# DDR16SS_DDR16SS_CTLPHY_WRAP_CTL_CFG_CTLCFG_0F308000h register map
Vendor: Texas Instruments
Registers are 32-bit, read-write, reset 0x0 unless marked. A register's access mark holds for its fields unless they carry their own. Offsets are as the file gives them; [hi:lo] are bit positions; {n}, {i} and the like mark numbered series.

## DDR16SS_CTLPHY_WRAP_CTL_CFG_CTLCFG (part 5 of 11)
0x5A0 DDR16SS_CTLPHY_WRAP_CTL_CFG_CTLCFG_DENALI_CTL_360 ro
  [31:0] OUT_OF_RANGE_ADDR_0 — Address of command that caused an out-of-range interrupt. READ-ONLY Reset Source: ctl_amod_g_rst_n
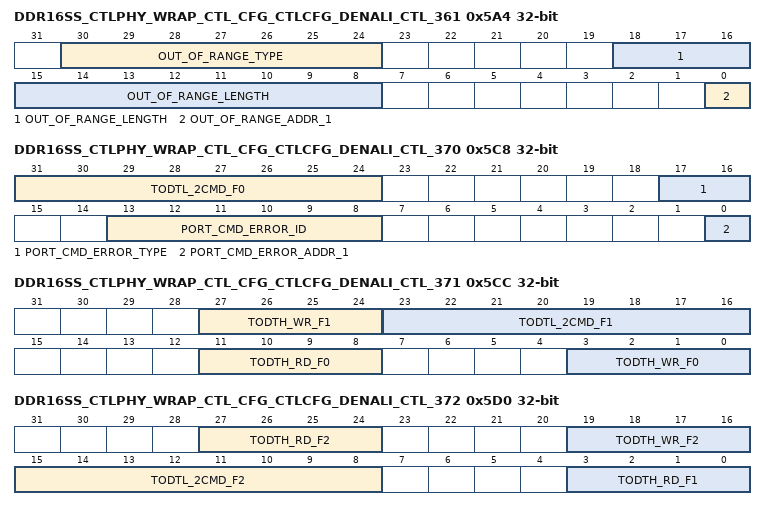
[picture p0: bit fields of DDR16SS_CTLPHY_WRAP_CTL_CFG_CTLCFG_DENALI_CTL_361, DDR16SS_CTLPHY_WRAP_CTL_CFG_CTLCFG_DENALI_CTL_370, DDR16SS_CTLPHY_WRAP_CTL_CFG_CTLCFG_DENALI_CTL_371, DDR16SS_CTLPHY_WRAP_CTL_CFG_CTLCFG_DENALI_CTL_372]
0x5A4 DDR16SS_CTLPHY_WRAP_CTL_CFG_CTLCFG_DENALI_CTL_361 ro
  [30:24] OUT_OF_RANGE_TYPE — Type of command that caused an out-of-range interrupt. READ-ONLY Reset Source: ctl_amod_g_rst_n
  [18:8] OUT_OF_RANGE_LENGTH — Length of command that caused an out-of-range interrupt. READ-ONLY Reset Source: ctl_amod_g_rst_n
  [0] OUT_OF_RANGE_ADDR_1 — Address of command that caused an out-of-range interrupt. READ-ONLY Reset Source: ctl_amod_g_rst_n
0x5A8 DDR16SS_CTLPHY_WRAP_CTL_CFG_CTLCFG_DENALI_CTL_362 ro
  [5:0] OUT_OF_RANGE_SOURCE_ID — Source ID of command that caused an out-of-range interrupt. READ-ONLY Reset Source: ctl_amod_g_rst_n
0x5AC DDR16SS_CTLPHY_WRAP_CTL_CFG_CTLCFG_DENALI_CTL_363 ro
  [31:0] BIST_EXP_DATA_0 — Expected data on BIST error. READ-ONLY Reset Source: ctl_amod_g_rst_n
0x5B0 DDR16SS_CTLPHY_WRAP_CTL_CFG_CTLCFG_DENALI_CTL_364 ro
  [31:0] BIST_EXP_DATA_1 — Expected data on BIST error. READ-ONLY Reset Source: ctl_amod_g_rst_n
0x5B4 DDR16SS_CTLPHY_WRAP_CTL_CFG_CTLCFG_DENALI_CTL_365 ro
  [31:0] BIST_FAIL_DATA_0 — Actual data on BIST error. READ-ONLY Reset Source: ctl_amod_g_rst_n
0x5B8 DDR16SS_CTLPHY_WRAP_CTL_CFG_CTLCFG_DENALI_CTL_366 ro
  [31:0] BIST_FAIL_DATA_1 — Actual data on BIST error. READ-ONLY Reset Source: ctl_amod_g_rst_n
0x5BC DDR16SS_CTLPHY_WRAP_CTL_CFG_CTLCFG_DENALI_CTL_367 ro
  [31:0] BIST_FAIL_ADDR_0 — Address of BIST error. READ-ONLY Reset Source: ctl_amod_g_rst_n
0x5C0 DDR16SS_CTLPHY_WRAP_CTL_CFG_CTLCFG_DENALI_CTL_368 ro
  [0] BIST_FAIL_ADDR_1 — Address of BIST error. READ-ONLY Reset Source: ctl_amod_g_rst_n
0x5C4 DDR16SS_CTLPHY_WRAP_CTL_CFG_CTLCFG_DENALI_CTL_369 ro
  [31:0] PORT_CMD_ERROR_ADDR_0 — Address of command that caused the PORT command error. READ-ONLY Reset Source: ctl_amod_g_rst_n
0x5C8 DDR16SS_CTLPHY_WRAP_CTL_CFG_CTLCFG_DENALI_CTL_370 access per field
  [31:24] TODTL_2CMD_F0 rw — Defines the DRAM delay from an ODT de-assertion to the next non-write, non-read command. FC=0 Reset Source: ctl_amod_g_rst_n
  [17:16] PORT_CMD_ERROR_TYPE ro — Type of error and access type that caused the PORT command error. READ-ONLY Reset Source: ctl_amod_g_rst_n
  [13:8] PORT_CMD_ERROR_ID ro — Source ID of command that caused the PORT command error. READ-ONLY Reset Source: ctl_amod_g_rst_n
  [0] PORT_CMD_ERROR_ADDR_1 ro — Address of command that caused the PORT command error. READ-ONLY Reset Source: ctl_amod_g_rst_n
0x5CC DDR16SS_CTLPHY_WRAP_CTL_CFG_CTLCFG_DENALI_CTL_371
  [27:24] TODTH_WR_F1 — Defines the DRAM minimum ODT high time after an ODT assertion for a write command. FC=1 Reset Source: ctl_amod_g_rst_n
  [23:16] TODTL_2CMD_F1 — Defines the DRAM delay from an ODT de-assertion to the next non-write, non-read command. FC=1 Reset Source: ctl_amod_g_rst_n
  [11:8] TODTH_RD_F0 — Defines the DRAM minimum ODT high time after an ODT assertion for a read command. FC=0 Reset Source: ctl_amod_g_rst_n
  [3:0] TODTH_WR_F0 — Defines the DRAM minimum ODT high time after an ODT assertion for a write command. FC=0 Reset Source: ctl_amod_g_rst_n
0x5D0 DDR16SS_CTLPHY_WRAP_CTL_CFG_CTLCFG_DENALI_CTL_372
  [27:24] TODTH_RD_F2 — Defines the DRAM minimum ODT high time after an ODT assertion for a read command. FC=2 Reset Source: ctl_amod_g_rst_n
  [19:16] TODTH_WR_F2 — Defines the DRAM minimum ODT high time after an ODT assertion for a write command. FC=2 Reset Source: ctl_amod_g_rst_n
  [15:8] TODTL_2CMD_F2 — Defines the DRAM delay from an ODT de-assertion to the next non-write, non-read command. FC=2 Reset Source: ctl_amod_g_rst_n
  [3:0] TODTH_RD_F1 — Defines the DRAM minimum ODT high time after an ODT assertion for a read command. FC=1 Reset Source: ctl_amod_g_rst_n
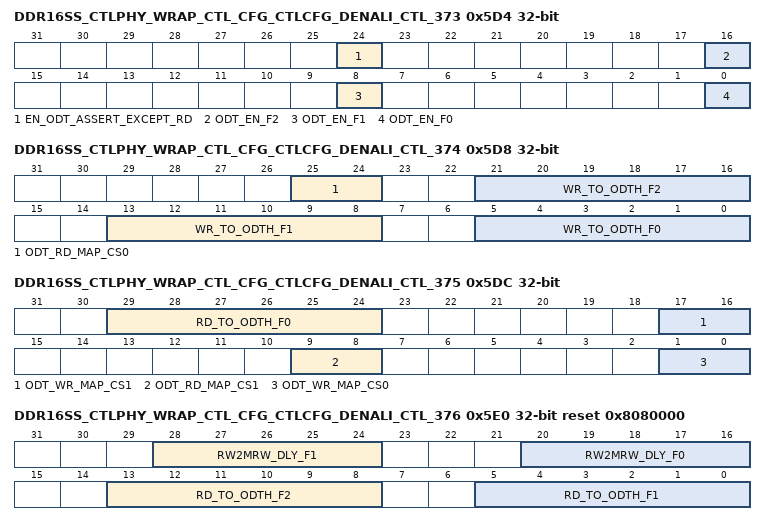
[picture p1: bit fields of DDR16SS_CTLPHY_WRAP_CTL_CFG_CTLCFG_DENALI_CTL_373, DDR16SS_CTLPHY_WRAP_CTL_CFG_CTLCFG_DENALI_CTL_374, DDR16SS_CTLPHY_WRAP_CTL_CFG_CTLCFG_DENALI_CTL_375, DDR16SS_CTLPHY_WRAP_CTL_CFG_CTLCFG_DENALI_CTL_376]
0x5D4 DDR16SS_CTLPHY_WRAP_CTL_CFG_CTLCFG_DENALI_CTL_373
  [24] EN_ODT_ASSERT_EXCEPT_RD — Enable controller to assert ODT at all times except during reads. Assumes single ODT pin connected. Set to 1 to enable. Reset Source: ctl_amod_g_rst_n
  [16] ODT_EN_F2 — Enable support of DRAM ODT. When enabled, controller will assert and de-assert ODT output to DRAM as needed. FC=2 Reset Source: ctl_amod_g_rst_n
  [8] ODT_EN_F1 — Enable support of DRAM ODT. When enabled, controller will assert and de-assert ODT output to DRAM as needed. FC=1 Reset Source: ctl_amod_g_rst_n
  [0] ODT_EN_F0 — Enable support of DRAM ODT. When enabled, controller will assert and de-assert ODT output to DRAM as needed. FC=0 Reset Source: ctl_amod_g_rst_n
0x5D8 DDR16SS_CTLPHY_WRAP_CTL_CFG_CTLCFG_DENALI_CTL_374
  [25:24] ODT_RD_MAP_CS0 — Determines which chip[s] will have termination when a read occurs. Set bit X to enable termination on csX when a read is performed. CS=0 Reset Source: ctl_amod_g_rst_n
  [21:16] WR_TO_ODTH_F2 — Defines the delay from a write command to ODT assertion. FC=2 Reset Source: ctl_amod_g_rst_n
  [13:8] WR_TO_ODTH_F1 — Defines the delay from a write command to ODT assertion. FC=1 Reset Source: ctl_amod_g_rst_n
  [5:0] WR_TO_ODTH_F0 — Defines the delay from a write command to ODT assertion. FC=0 Reset Source: ctl_amod_g_rst_n
0x5DC DDR16SS_CTLPHY_WRAP_CTL_CFG_CTLCFG_DENALI_CTL_375
  [29:24] RD_TO_ODTH_F0 — Defines the delay from a read command to ODT assertion. FC=0 Reset Source: ctl_amod_g_rst_n
  [17:16] ODT_WR_MAP_CS1 — Determines which chip[s] will have termination when a write occurs. Set bit X to enable termination on csX when a write is performed. CS=1 Reset Source: ctl_amod_g_rst_n
  [9:8] ODT_RD_MAP_CS1 — Determines which chip[s] will have termination when a read occurs. Set bit X to enable termination on csX when a read is performed. CS=1 Reset Source: ctl_amod_g_rst_n
  [1:0] ODT_WR_MAP_CS0 — Determines which chip[s] will have termination when a write occurs. Set bit X to enable termination on csX when a write is performed. CS=0 Reset Source: ctl_amod_g_rst_n
0x5E0 DDR16SS_CTLPHY_WRAP_CTL_CFG_CTLCFG_DENALI_CTL_376 reset 0x8080000
  [28:24] RW2MRW_DLY_F1 — Additional delay to insert between read or write and mode_reg_write. Allowed programming dependent on memory system. FC=1 Reset Source: ctl_amod_g_rst_n
  [20:16] RW2MRW_DLY_F0 — Additional delay to insert between read or write and mode_reg_write. Allowed programming dependent on memory system. FC=0 Reset Source: ctl_amod_g_rst_n
  [13:8] RD_TO_ODTH_F2 — Defines the delay from a read command to ODT assertion. FC=2 Reset Source: ctl_amod_g_rst_n
  [5:0] RD_TO_ODTH_F1 — Defines the delay from a read command to ODT assertion. FC=1 Reset Source: ctl_amod_g_rst_n
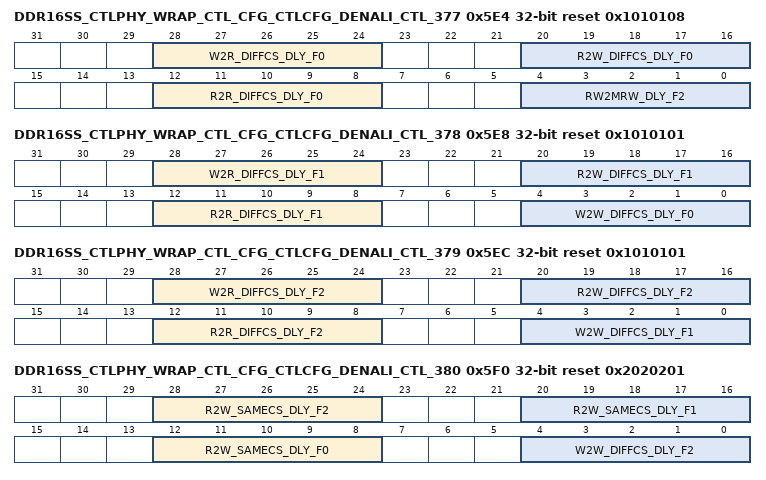
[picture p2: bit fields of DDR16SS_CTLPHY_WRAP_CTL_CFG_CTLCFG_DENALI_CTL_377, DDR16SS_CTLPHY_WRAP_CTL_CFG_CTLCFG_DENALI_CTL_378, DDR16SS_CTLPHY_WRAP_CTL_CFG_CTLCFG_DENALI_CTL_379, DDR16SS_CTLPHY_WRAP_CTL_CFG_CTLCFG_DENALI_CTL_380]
0x5E4 DDR16SS_CTLPHY_WRAP_CTL_CFG_CTLCFG_DENALI_CTL_377 reset 0x1010108
  [28:24] W2R_DIFFCS_DLY_F0 — Additional delay to insert between writes and reads to different chip selects. Allowed programming dependent on memory system. FC=0 Reset Source: ctl_amod_g_rst_n
  [20:16] R2W_DIFFCS_DLY_F0 — Additional delay to insert between reads and writes to different chip selects. Program to a non-zero value. FC=0 Reset Source: ctl_amod_g_rst_n
  [12:8] R2R_DIFFCS_DLY_F0 — Additional delay to insert between reads to different chip selects. Program to a non-zero value. FC=0 Reset Source: ctl_amod_g_rst_n
  [4:0] RW2MRW_DLY_F2 — Additional delay to insert between read or write and mode_reg_write. Allowed programming dependent on memory system. FC=2 Reset Source: ctl_amod_g_rst_n
0x5E8 DDR16SS_CTLPHY_WRAP_CTL_CFG_CTLCFG_DENALI_CTL_378 reset 0x1010101
  [28:24] W2R_DIFFCS_DLY_F1 — Additional delay to insert between writes and reads to different chip selects. Allowed programming dependent on memory system. FC=1 Reset Source: ctl_amod_g_rst_n
  [20:16] R2W_DIFFCS_DLY_F1 — Additional delay to insert between reads and writes to different chip selects. Program to a non-zero value. FC=1 Reset Source: ctl_amod_g_rst_n
  [12:8] R2R_DIFFCS_DLY_F1 — Additional delay to insert between reads to different chip selects. Program to a non-zero value. FC=1 Reset Source: ctl_amod_g_rst_n
  [4:0] W2W_DIFFCS_DLY_F0 — Additional delay to insert between writes to different chip selects. Program to a non-zero value. FC=0 Reset Source: ctl_amod_g_rst_n
0x5EC DDR16SS_CTLPHY_WRAP_CTL_CFG_CTLCFG_DENALI_CTL_379 reset 0x1010101
  [28:24] W2R_DIFFCS_DLY_F2 — Additional delay to insert between writes and reads to different chip selects. Allowed programming dependent on memory system. FC=2 Reset Source: ctl_amod_g_rst_n
  [20:16] R2W_DIFFCS_DLY_F2 — Additional delay to insert between reads and writes to different chip selects. Program to a non-zero value. FC=2 Reset Source: ctl_amod_g_rst_n
  [12:8] R2R_DIFFCS_DLY_F2 — Additional delay to insert between reads to different chip selects. Program to a non-zero value. FC=2 Reset Source: ctl_amod_g_rst_n
  [4:0] W2W_DIFFCS_DLY_F1 — Additional delay to insert between writes to different chip selects. Program to a non-zero value. FC=1 Reset Source: ctl_amod_g_rst_n
0x5F0 DDR16SS_CTLPHY_WRAP_CTL_CFG_CTLCFG_DENALI_CTL_380 reset 0x2020201
  [28:24] R2W_SAMECS_DLY_F2 — Additional delay to insert between reads and writes to the same chip select. Program to a non-zero value. FC=2 Reset Source: ctl_amod_g_rst_n
  [20:16] R2W_SAMECS_DLY_F1 — Additional delay to insert between reads and writes to the same chip select. Program to a non-zero value. FC=1 Reset Source: ctl_amod_g_rst_n
  [12:8] R2W_SAMECS_DLY_F0 — Additional delay to insert between reads and writes to the same chip select. Program to a non-zero value. FC=0 Reset Source: ctl_amod_g_rst_n
  [4:0] W2W_DIFFCS_DLY_F2 — Additional delay to insert between writes to different chip selects. Program to a non-zero value. FC=2 Reset Source: ctl_amod_g_rst_n
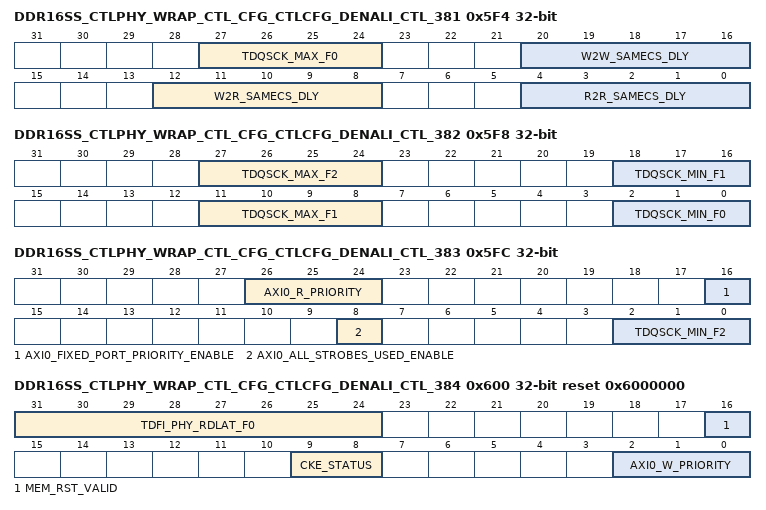
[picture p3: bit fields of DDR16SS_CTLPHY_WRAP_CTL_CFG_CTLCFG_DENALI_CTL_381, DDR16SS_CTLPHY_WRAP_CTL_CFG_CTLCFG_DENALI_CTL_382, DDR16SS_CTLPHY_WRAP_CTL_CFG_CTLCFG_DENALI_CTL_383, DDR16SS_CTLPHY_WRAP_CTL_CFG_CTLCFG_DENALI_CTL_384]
0x5F4 DDR16SS_CTLPHY_WRAP_CTL_CFG_CTLCFG_DENALI_CTL_381
  [27:24] TDQSCK_MAX_F0 — Additional delay needed for tDQSCK. FC=0 Reset Source: ctl_amod_g_rst_n
  [20:16] W2W_SAMECS_DLY — Additional delay to insert between two writes to the same chip select. Any value including 0 supported. Reset Source: ctl_amod_g_rst_n
  [12:8] W2R_SAMECS_DLY — Additional delay to insert between writes and reads to the same chip select. Reset Source: ctl_amod_g_rst_n
  [4:0] R2R_SAMECS_DLY — Additional delay to insert between two reads to the same chip select. Any value including 0 supported. Reset Source: ctl_amod_g_rst_n
0x5F8 DDR16SS_CTLPHY_WRAP_CTL_CFG_CTLCFG_DENALI_CTL_382
  [27:24] TDQSCK_MAX_F2 — Additional delay needed for tDQSCK. FC=2 Reset Source: ctl_amod_g_rst_n
  [18:16] TDQSCK_MIN_F1 — Additional delay needed for tDQSCK. FC=1 Reset Source: ctl_amod_g_rst_n
  [11:8] TDQSCK_MAX_F1 — Additional delay needed for tDQSCK. FC=1 Reset Source: ctl_amod_g_rst_n
  [2:0] TDQSCK_MIN_F0 — Additional delay needed for tDQSCK. FC=0 Reset Source: ctl_amod_g_rst_n
0x5FC DDR16SS_CTLPHY_WRAP_CTL_CFG_CTLCFG_DENALI_CTL_383
  [26:24] AXI0_R_PRIORITY — Priority of read commands from AXI port 0. 0 is the highest priority. This may only be changed before initialization begins or when the controller is quiescent, there is no data in the port FIFOs, and the AXI0_FIXED_PORT_PRIORITY_ENABLE parameter is low. Reset Source: ctl_amod_g_rst_n
  [16] AXI0_FIXED_PORT_PRIORITY_ENABLE — Defines the priority control for AXI port 0 as per-port or per-command. Set to 1 for per-port with priority defined through the AXI.0._R_PRIORITY and AXI.0._W_PRIORITY parameters. Clear to 0 for per-command. Reset Source: ctl_amod_g_rst_n
  [8] AXI0_ALL_STROBES_USED_ENABLE — Enables use of the AWALLSTRB signal for AXI port 0. Set to 1 to enable. Reset Source: ctl_amod_g_rst_n
  [2:0] TDQSCK_MIN_F2 — Additional delay needed for tDQSCK. FC=2 Reset Source: ctl_amod_g_rst_n
0x600 DDR16SS_CTLPHY_WRAP_CTL_CFG_CTLCFG_DENALI_CTL_384 access per field reset 0x6000000
  [31:24] TDFI_PHY_RDLAT_F0 rw — Defines the DFI tPHY_RDLAT timing parameter [in DFI PHY clocks], the maximum cycles between a dfi_rddata_en assertion and a dfi_rddata_valid assertion. FC=0 Reset Source: ctl_amod_g_rst_n
  [16] MEM_RST_VALID ro — Register access to mem_rst_valid signal. READ-ONLY Reset Source: ctl_amod_g_rst_n
  [9:8] CKE_STATUS ro — Register access to cke_status signal. READ-ONLY Reset Source: ctl_amod_g_rst_n
  [2:0] AXI0_W_PRIORITY rw — Priority of write commands from AXI port 0. 0 is the highest priority. This may only be changed before initialization begins or when the controller is quiescent, there is no data in the port FIFOs, and the AXI0_FIXED_PORT_PRIORITY_ENABLE parameter is low. Reset Source: ctl_amod_g_rst_n
0x604 DDR16SS_CTLPHY_WRAP_CTL_CFG_CTLCFG_DENALI_CTL_385
  [20:0] TDFI_CTRLUPD_MAX_F0 — Defines the DFI tCTRLUPD_MAX timing parameter [in DFI clocks], the maximum cycles that dfi_ctrlupd_req can be asserted. If programmed to a non-zero, a timing violation will cause an interrupt and bit [0] set in the UPDATE_ERROR_STATUS parameter. FC=0 Reset Source: ctl_amod_g_rst_n
{0x0+4i} DDR16SS_CTLPHY_WRAP_CTL_CFG_CTLCFG_DENALI_CTL_{i} (i=386..389)
  [31:0] TDFI_PHYUPD_TYPE{i-386}_F0 — Defines the DFI tPHYUPD_TYPE{i-386} timing parameter [in DFI clocks], the maximum cycles that dfi_phyupd_req can assert after dfi_phyupd_ack for dfi_phyupd_type {i-386}. If programmed to a non-zero, a timing violation will cause an interrupt and bit [{i-385}] set in the UPDATE_ERROR_STATUS parameter. FC=0 Reset Source: ctl_amod_g_rst_n
0x618 DDR16SS_CTLPHY_WRAP_CTL_CFG_CTLCFG_DENALI_CTL_390
  [22:0] TDFI_PHYUPD_RESP_F0 — Defines the DFI tPHYUPD_RESP timing parameter [in DFI clocks], the maximum cycles between a dfi_phyupd_req assertion and a dfi_phyupd_ack assertion. If programmed to a non-zero, a timing violation will cause an interrupt and bit [5] set in the UPDATE_ERROR_STATUS parameter. FC=0 Reset Source: ctl_amod_g_rst_n
0x61C DDR16SS_CTLPHY_WRAP_CTL_CFG_CTLCFG_DENALI_CTL_391
  [31:0] TDFI_CTRLUPD_INTERVAL_F0 — Defines the DFI tCTRLUPD_INTERVAL timing parameter [in DFI clocks], the maximum cycles between dfi_ctrlupd_req assertions. If programmed to a non-zero, a timing violation will cause an interrupt and bit [6] set in the UPDATE_ERROR_STATUS parameter. FC=0 Reset Source: ctl_amod_g_rst_n
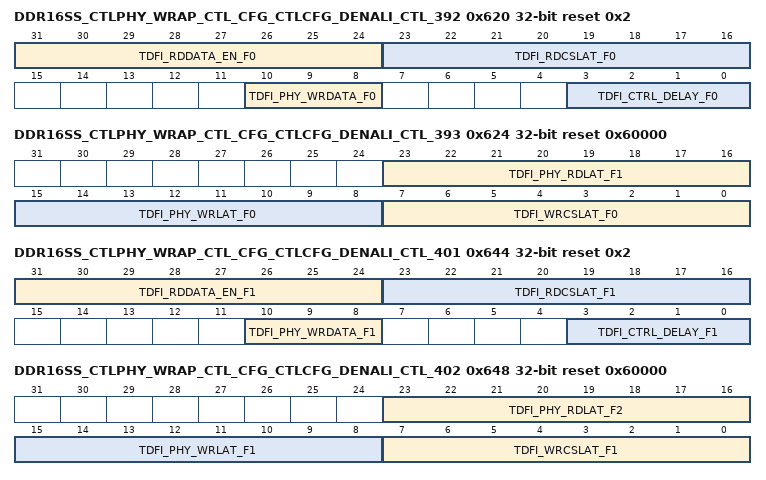
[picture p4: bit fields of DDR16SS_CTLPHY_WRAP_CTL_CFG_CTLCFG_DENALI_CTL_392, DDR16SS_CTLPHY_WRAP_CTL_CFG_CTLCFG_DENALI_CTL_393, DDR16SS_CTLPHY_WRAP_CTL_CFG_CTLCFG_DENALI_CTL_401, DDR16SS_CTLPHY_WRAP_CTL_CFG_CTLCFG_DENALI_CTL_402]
0x620 DDR16SS_CTLPHY_WRAP_CTL_CFG_CTLCFG_DENALI_CTL_392 reset 0x2
  [31:24] TDFI_RDDATA_EN_F0 — DFI tRDDATA_EN timing parameter. This is the number of DFI data phases between a read command and the first assertion of dfi_rddata_en_pN. FC=0 Reset Source: ctl_amod_g_rst_n
  [23:16] TDFI_RDCSLAT_F0 — Defines the DFI tPHY_RDCSLAT timing parameter [in DFI PHY clocks], the maximum cycles between a read command and a dfi_rddata_cs_n assertion. FC=0 Reset Source: ctl_amod_g_rst_n
  [10:8] TDFI_PHY_WRDATA_F0 — Defines the DFI tPHY_WRDATA timing parameter [in DFI PHY clocks], the maximum cycles between a dfi_wrdata_en assertion and a dfi_wrdata signal. FC=0 Reset Source: ctl_amod_g_rst_n
  [3:0] TDFI_CTRL_DELAY_F0 — Defines the DFI tCTRL_DELAY timing parameter [in DFI clocks], the delay between a DFI command change and a memory command. FC=0 Reset Source: ctl_amod_g_rst_n
0x624 DDR16SS_CTLPHY_WRAP_CTL_CFG_CTLCFG_DENALI_CTL_393 reset 0x60000
  [23:16] TDFI_PHY_RDLAT_F1 — Defines the DFI tPHY_RDLAT timing parameter [in DFI PHY clocks], the maximum cycles between a dfi_rddata_en assertion and a dfi_rddata_valid assertion. FC=1 Reset Source: ctl_amod_g_rst_n
  [15:8] TDFI_PHY_WRLAT_F0 — DFI tPHY_WRLAT timing parameter. This is the number of DFI data phases between a write command and the first assertion of dfi_wrdata_en_pN. FC=0 Reset Source: ctl_amod_g_rst_n
  [7:0] TDFI_WRCSLAT_F0 — Defines the DFI tPHY_WRCSLAT timing parameter [in DFI PHY clocks], the maximum cycles between a write command and a dfi_wrdata_cs_n assertion. FC=0 Reset Source: ctl_amod_g_rst_n
0x628 DDR16SS_CTLPHY_WRAP_CTL_CFG_CTLCFG_DENALI_CTL_394
  [20:0] TDFI_CTRLUPD_MAX_F1 — Defines the DFI tCTRLUPD_MAX timing parameter [in DFI clocks], the maximum cycles that dfi_ctrlupd_req can be asserted. If programmed to a non-zero, a timing violation will cause an interrupt and bit [0] set in the UPDATE_ERROR_STATUS parameter. FC=1 Reset Source: ctl_amod_g_rst_n
{0x0+4i} DDR16SS_CTLPHY_WRAP_CTL_CFG_CTLCFG_DENALI_CTL_{i} (i=395..398)
  [31:0] TDFI_PHYUPD_TYPE{i-395}_F1 — Defines the DFI tPHYUPD_TYPE{i-395} timing parameter [in DFI clocks], the maximum cycles that dfi_phyupd_req can assert after dfi_phyupd_ack for dfi_phyupd_type {i-395}. If programmed to a non-zero, a timing violation will cause an interrupt and bit [{i-394}] set in the UPDATE_ERROR_STATUS parameter. FC=1 Reset Source: ctl_amod_g_rst_n
0x63C DDR16SS_CTLPHY_WRAP_CTL_CFG_CTLCFG_DENALI_CTL_399
  [22:0] TDFI_PHYUPD_RESP_F1 — Defines the DFI tPHYUPD_RESP timing parameter [in DFI clocks], the maximum cycles between a dfi_phyupd_req assertion and a dfi_phyupd_ack assertion. If programmed to a non-zero, a timing violation will cause an interrupt and bit [5] set in the UPDATE_ERROR_STATUS parameter. FC=1 Reset Source: ctl_amod_g_rst_n
0x640 DDR16SS_CTLPHY_WRAP_CTL_CFG_CTLCFG_DENALI_CTL_400
  [31:0] TDFI_CTRLUPD_INTERVAL_F1 — Defines the DFI tCTRLUPD_INTERVAL timing parameter [in DFI clocks], the maximum cycles between dfi_ctrlupd_req assertions. If programmed to a non-zero, a timing violation will cause an interrupt and bit [6] set in the UPDATE_ERROR_STATUS parameter. FC=1 Reset Source: ctl_amod_g_rst_n
0x644 DDR16SS_CTLPHY_WRAP_CTL_CFG_CTLCFG_DENALI_CTL_401 reset 0x2
  [31:24] TDFI_RDDATA_EN_F1 — DFI tRDDATA_EN timing parameter. This is the number of DFI data phases between a read command and the first assertion of dfi_rddata_en_pN. FC=1 Reset Source: ctl_amod_g_rst_n
  [23:16] TDFI_RDCSLAT_F1 — Defines the DFI tPHY_RDCSLAT timing parameter [in DFI PHY clocks], the maximum cycles between a read command and a dfi_rddata_cs_n assertion. FC=1 Reset Source: ctl_amod_g_rst_n
  [10:8] TDFI_PHY_WRDATA_F1 — Defines the DFI tPHY_WRDATA timing parameter [in DFI PHY clocks], the maximum cycles between a dfi_wrdata_en assertion and a dfi_wrdata signal. FC=1 Reset Source: ctl_amod_g_rst_n
  [3:0] TDFI_CTRL_DELAY_F1 — Defines the DFI tCTRL_DELAY timing parameter [in DFI clocks], the delay between a DFI command change and a memory command. FC=1 Reset Source: ctl_amod_g_rst_n
0x648 DDR16SS_CTLPHY_WRAP_CTL_CFG_CTLCFG_DENALI_CTL_402 reset 0x60000
  [23:16] TDFI_PHY_RDLAT_F2 — Defines the DFI tPHY_RDLAT timing parameter [in DFI PHY clocks], the maximum cycles between a dfi_rddata_en assertion and a dfi_rddata_valid assertion. FC=2 Reset Source: ctl_amod_g_rst_n
  [15:8] TDFI_PHY_WRLAT_F1 — DFI tPHY_WRLAT timing parameter. This is the number of DFI data phases between a write command and the first assertion of dfi_wrdata_en_pN. FC=1 Reset Source: ctl_amod_g_rst_n
  [7:0] TDFI_WRCSLAT_F1 — Defines the DFI tPHY_WRCSLAT timing parameter [in DFI PHY clocks], the maximum cycles between a write command and a dfi_wrdata_cs_n assertion. FC=1 Reset Source: ctl_amod_g_rst_n
0x64C DDR16SS_CTLPHY_WRAP_CTL_CFG_CTLCFG_DENALI_CTL_403
  [20:0] TDFI_CTRLUPD_MAX_F2 — Defines the DFI tCTRLUPD_MAX timing parameter [in DFI clocks], the maximum cycles that dfi_ctrlupd_req can be asserted. If programmed to a non-zero, a timing violation will cause an interrupt and bit [0] set in the UPDATE_ERROR_STATUS parameter. FC=2 Reset Source: ctl_amod_g_rst_n
{0x0+4i} DDR16SS_CTLPHY_WRAP_CTL_CFG_CTLCFG_DENALI_CTL_{i} (i=404..407)
  [31:0] TDFI_PHYUPD_TYPE{i-404}_F2 — Defines the DFI tPHYUPD_TYPE{i-404} timing parameter [in DFI clocks], the maximum cycles that dfi_phyupd_req can assert after dfi_phyupd_ack for dfi_phyupd_type {i-404}. If programmed to a non-zero, a timing violation will cause an interrupt and bit [{i-403}] set in the UPDATE_ERROR_STATUS parameter. FC=2 Reset Source: ctl_amod_g_rst_n
0x660 DDR16SS_CTLPHY_WRAP_CTL_CFG_CTLCFG_DENALI_CTL_408
  [22:0] TDFI_PHYUPD_RESP_F2 — Defines the DFI tPHYUPD_RESP timing parameter [in DFI clocks], the maximum cycles between a dfi_phyupd_req assertion and a dfi_phyupd_ack assertion. If programmed to a non-zero, a timing violation will cause an interrupt and bit [5] set in the UPDATE_ERROR_STATUS parameter. FC=2 Reset Source: ctl_amod_g_rst_n
0x664 DDR16SS_CTLPHY_WRAP_CTL_CFG_CTLCFG_DENALI_CTL_409
  [31:0] TDFI_CTRLUPD_INTERVAL_F2 — Defines the DFI tCTRLUPD_INTERVAL timing parameter [in DFI clocks], the maximum cycles between dfi_ctrlupd_req assertions. If programmed to a non-zero, a timing violation will cause an interrupt and bit [6] set in the UPDATE_ERROR_STATUS parameter. FC=2 Reset Source: ctl_amod_g_rst_n
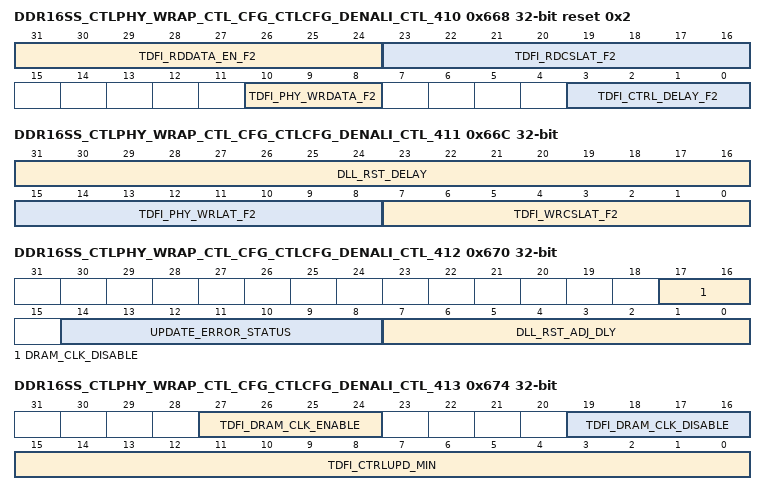
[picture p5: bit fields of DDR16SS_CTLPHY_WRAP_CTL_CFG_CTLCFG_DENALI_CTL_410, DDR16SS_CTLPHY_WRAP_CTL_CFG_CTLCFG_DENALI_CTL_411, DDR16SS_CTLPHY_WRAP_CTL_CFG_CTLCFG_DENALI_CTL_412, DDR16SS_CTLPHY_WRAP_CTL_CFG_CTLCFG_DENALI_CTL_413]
0x668 DDR16SS_CTLPHY_WRAP_CTL_CFG_CTLCFG_DENALI_CTL_410 reset 0x2
  [31:24] TDFI_RDDATA_EN_F2 — DFI tRDDATA_EN timing parameter. This is the number of DFI data phases between a read command and the first assertion of dfi_rddata_en_pN. FC=2 Reset Source: ctl_amod_g_rst_n
  [23:16] TDFI_RDCSLAT_F2 — Defines the DFI tPHY_RDCSLAT timing parameter [in DFI PHY clocks], the maximum cycles between a read command and a dfi_rddata_cs_n assertion. FC=2 Reset Source: ctl_amod_g_rst_n
  [10:8] TDFI_PHY_WRDATA_F2 — Defines the DFI tPHY_WRDATA timing parameter [in DFI PHY clocks], the maximum cycles between a dfi_wrdata_en assertion and a dfi_wrdata signal. FC=2 Reset Source: ctl_amod_g_rst_n
  [3:0] TDFI_CTRL_DELAY_F2 — Defines the DFI tCTRL_DELAY timing parameter [in DFI clocks], the delay between a DFI command change and a memory command. FC=2 Reset Source: ctl_amod_g_rst_n
0x66C DDR16SS_CTLPHY_WRAP_CTL_CFG_CTLCFG_DENALI_CTL_411
  [31:16] DLL_RST_DELAY — Minimum cycles required for DLL reset signal dll_rst_n to be held. If this signal is not being used by the PHY, this parameter may be ignored. Reset Source: ctl_amod_g_rst_n
  [15:8] TDFI_PHY_WRLAT_F2 — DFI tPHY_WRLAT timing parameter. This is the number of DFI data phases between a write command and the first assertion of dfi_wrdata_en_pN. FC=2 Reset Source: ctl_amod_g_rst_n
  [7:0] TDFI_WRCSLAT_F2 — Defines the DFI tPHY_WRCSLAT timing parameter [in DFI PHY clocks], the maximum cycles between a write command and a dfi_wrdata_cs_n assertion. FC=2 Reset Source: ctl_amod_g_rst_n
0x670 DDR16SS_CTLPHY_WRAP_CTL_CFG_CTLCFG_DENALI_CTL_412 access per field
  [17:16] DRAM_CLK_DISABLE rw — Set value for the dfi_dram_clk_disable signal. Bit [0] controls cs0, bit [1] controls cs1, etc. Set each bit to 1 to disable. Reset Source: ctl_amod_g_rst_n
  [14:8] UPDATE_ERROR_STATUS ro — Identifies the source of any DFI MC-initiated or PHY-initiated update errors. Value of 1 indicates a timing violation of the associated timing parameter. READ-ONLY Reset Source: ctl_amod_g_rst_n
  [7:0] DLL_RST_ADJ_DLY rw — Minimum cycles after setting master delay in DLL until the DLL reset signal dll_rst_n may be asserted. If this signal is not being used by the PHY, this parameter may be ignored. Reset Source: ctl_amod_g_rst_n
0x674 DDR16SS_CTLPHY_WRAP_CTL_CFG_CTLCFG_DENALI_CTL_413
  [27:24] TDFI_DRAM_CLK_ENABLE — Defines the DFI tDRAM_CLK_ENABLE timing parameter [in DFI clocks], the delay between a dfi_dram_clk_disable de-assertion and the memory clock enable. Reset Source: ctl_amod_g_rst_n
  [19:16] TDFI_DRAM_CLK_DISABLE — Defines the DFI tDRAM_CLK_DISABLE timing parameter [in DFI clocks], the delay between a dfi_dram_clock_disable assertion and the memory clock disable. Reset Source: ctl_amod_g_rst_n
  [15:0] TDFI_CTRLUPD_MIN — Defines the DFI tCTRLUPD_MIN timing parameter [in DFI clocks], the minimum cycles that dfi_ctrlupd_req must be asserted. Reset Source: ctl_amod_g_rst_n
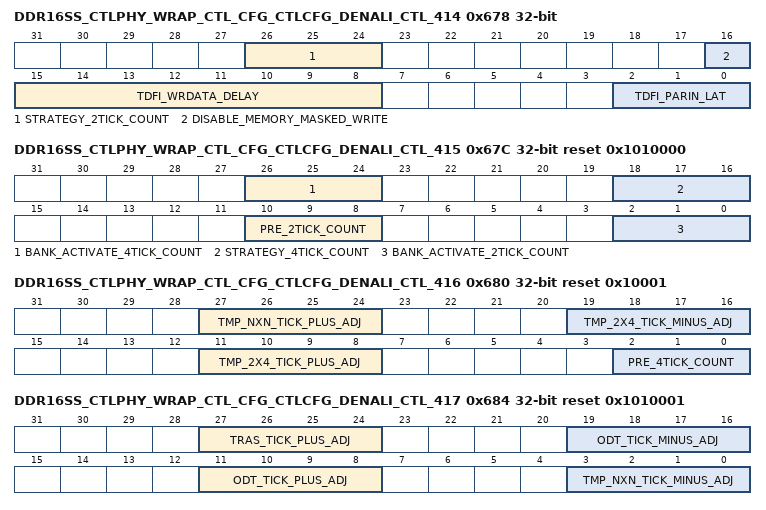
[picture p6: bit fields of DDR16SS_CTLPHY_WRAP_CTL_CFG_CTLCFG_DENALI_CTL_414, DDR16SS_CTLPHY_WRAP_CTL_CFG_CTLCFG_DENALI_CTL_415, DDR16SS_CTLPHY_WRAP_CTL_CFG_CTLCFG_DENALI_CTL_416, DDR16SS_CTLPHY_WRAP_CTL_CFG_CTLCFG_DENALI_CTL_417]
0x678 DDR16SS_CTLPHY_WRAP_CTL_CFG_CTLCFG_DENALI_CTL_414
  [26:24] STRATEGY_2TICK_COUNT — NEED TO FiLL IN . Reset Source: ctl_amod_g_rst_n
  [16] DISABLE_MEMORY_MASKED_WRITE — Restricts the controller from masked write commands. Set to 1 to not issue these commands. Only used if connected to an LPDDR4 device. Reset Source: ctl_amod_g_rst_n
  [15:8] TDFI_WRDATA_DELAY — Defines the tWRDATA_DELAY timing parameter [in DFI PHY clocks], the maximum cycles between when the dfi_wrdata_en signal is asserted and when the corresponding write data transfer is completed on the DRAM bus. Reset Source: ctl_amod_g_rst_n
  [2:0] TDFI_PARIN_LAT — Defines the DFI tPARIN_LAT timing parameter [in DFI PHY clocks], the maximum cycles between a DFI command and a dfi_parity_in signal assertion. Reset Source: ctl_amod_g_rst_n
0x67C DDR16SS_CTLPHY_WRAP_CTL_CFG_CTLCFG_DENALI_CTL_415 reset 0x1010000
  [26:24] BANK_ACTIVATE_4TICK_COUNT — NEED TO FiLL IN . Reset Source: ctl_amod_g_rst_n
  [18:16] STRATEGY_4TICK_COUNT — NEED TO FiLL IN . Reset Source: ctl_amod_g_rst_n
  [10:8] PRE_2TICK_COUNT — NEED TO FiLL IN . Reset Source: ctl_amod_g_rst_n
  [2:0] BANK_ACTIVATE_2TICK_COUNT — NEED TO FiLL IN . Reset Source: ctl_amod_g_rst_n
0x680 DDR16SS_CTLPHY_WRAP_CTL_CFG_CTLCFG_DENALI_CTL_416 reset 0x10001
  [27:24] TMP_NXN_TICK_PLUS_ADJ — NEED TO FiLL IN . Reset Source: ctl_amod_g_rst_n
  [19:16] TMP_2X4_TICK_MINUS_ADJ — NEED TO FiLL IN . Reset Source: ctl_amod_g_rst_n
  [11:8] TMP_2X4_TICK_PLUS_ADJ — NEED TO FiLL IN . Reset Source: ctl_amod_g_rst_n
  [2:0] PRE_4TICK_COUNT — NEED TO FiLL IN . Reset Source: ctl_amod_g_rst_n
0x684 DDR16SS_CTLPHY_WRAP_CTL_CFG_CTLCFG_DENALI_CTL_417 reset 0x1010001
  [27:24] TRAS_TICK_PLUS_ADJ — NEED TO FiLL IN . Reset Source: ctl_amod_g_rst_n
  [19:16] ODT_TICK_MINUS_ADJ — NEED TO FiLL IN . Reset Source: ctl_amod_g_rst_n
  [11:8] ODT_TICK_PLUS_ADJ — NEED TO FiLL IN . Reset Source: ctl_amod_g_rst_n
  [3:0] TMP_NXN_TICK_MINUS_ADJ — NEED TO FiLL IN . Reset Source: ctl_amod_g_rst_n
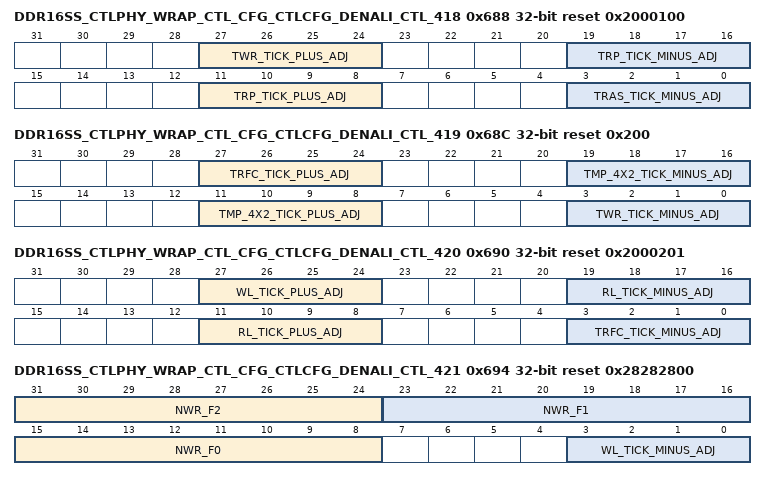
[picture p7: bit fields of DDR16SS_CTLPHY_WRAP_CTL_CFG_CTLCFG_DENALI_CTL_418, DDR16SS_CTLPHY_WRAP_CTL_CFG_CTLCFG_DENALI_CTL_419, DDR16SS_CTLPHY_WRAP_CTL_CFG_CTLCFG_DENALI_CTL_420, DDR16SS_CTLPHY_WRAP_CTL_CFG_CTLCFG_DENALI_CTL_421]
0x688 DDR16SS_CTLPHY_WRAP_CTL_CFG_CTLCFG_DENALI_CTL_418 reset 0x2000100
  [27:24] TWR_TICK_PLUS_ADJ — NEED TO FiLL IN . Reset Source: ctl_amod_g_rst_n
  [19:16] TRP_TICK_MINUS_ADJ — NEED TO FiLL IN . Reset Source: ctl_amod_g_rst_n
  [11:8] TRP_TICK_PLUS_ADJ — NEED TO FiLL IN . Reset Source: ctl_amod_g_rst_n
  [3:0] TRAS_TICK_MINUS_ADJ — NEED TO FiLL IN . Reset Source: ctl_amod_g_rst_n
0x68C DDR16SS_CTLPHY_WRAP_CTL_CFG_CTLCFG_DENALI_CTL_419 reset 0x200
  [27:24] TRFC_TICK_PLUS_ADJ — NEED TO FiLL IN . Reset Source: ctl_amod_g_rst_n
  [19:16] TMP_4X2_TICK_MINUS_ADJ — NEED TO FiLL IN . Reset Source: ctl_amod_g_rst_n
  [11:8] TMP_4X2_TICK_PLUS_ADJ — NEED TO FiLL IN . Reset Source: ctl_amod_g_rst_n
  [3:0] TWR_TICK_MINUS_ADJ — NEED TO FiLL IN . Reset Source: ctl_amod_g_rst_n
0x690 DDR16SS_CTLPHY_WRAP_CTL_CFG_CTLCFG_DENALI_CTL_420 reset 0x2000201
  [27:24] WL_TICK_PLUS_ADJ — NEED TO FiLL IN . Reset Source: ctl_amod_g_rst_n
  [19:16] RL_TICK_MINUS_ADJ — NEED TO FiLL IN . Reset Source: ctl_amod_g_rst_n
  [11:8] RL_TICK_PLUS_ADJ — NEED TO FiLL IN . Reset Source: ctl_amod_g_rst_n
  [3:0] TRFC_TICK_MINUS_ADJ — NEED TO FiLL IN . Reset Source: ctl_amod_g_rst_n
0x694 DDR16SS_CTLPHY_WRAP_CTL_CFG_CTLCFG_DENALI_CTL_421 reset 0x28282800
  [31:24] NWR_F2 — DRAM NWR value in cycles. FC=2 Reset Source: ctl_amod_g_rst_n
  [23:16] NWR_F1 — DRAM NWR value in cycles. FC=1 Reset Source: ctl_amod_g_rst_n
  [15:8] NWR_F0 — DRAM NWR value in cycles. FC=0 Reset Source: ctl_amod_g_rst_n
  [3:0] WL_TICK_MINUS_ADJ — NEED TO FiLL IN . Reset Source: ctl_amod_g_rst_n
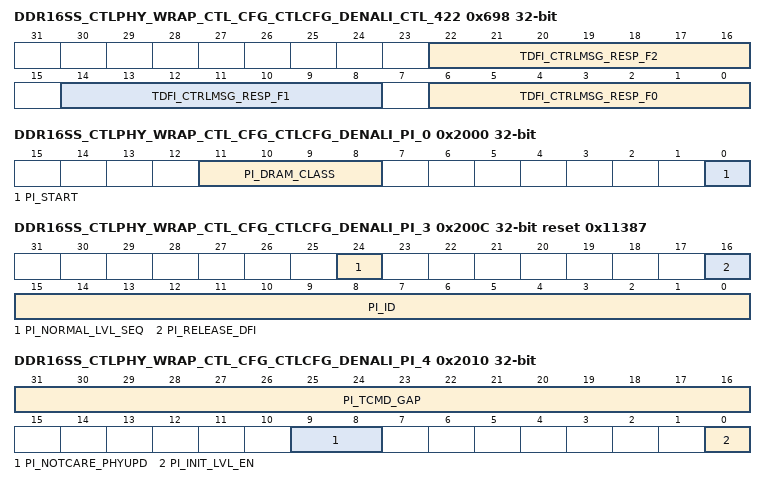
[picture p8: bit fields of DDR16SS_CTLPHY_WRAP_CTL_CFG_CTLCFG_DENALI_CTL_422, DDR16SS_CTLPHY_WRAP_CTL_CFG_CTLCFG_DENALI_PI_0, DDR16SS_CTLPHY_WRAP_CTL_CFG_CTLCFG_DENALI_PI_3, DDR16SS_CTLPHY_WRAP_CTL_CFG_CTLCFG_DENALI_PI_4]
0x698 DDR16SS_CTLPHY_WRAP_CTL_CFG_CTLCFG_DENALI_CTL_422
  [22:16] TDFI_CTRLMSG_RESP_F2 — Defines the DFI tCTRLMSG_RESP timing parameter [in DFI clocks], the maximum number of DFI clocks allowed for dfi_ctrlmsg_ack to assert after dfi_ctrlmsg_req goes high. FC=2 Reset Source: ctl_amod_g_rst_n
  [14:8] TDFI_CTRLMSG_RESP_F1 — Defines the DFI tCTRLMSG_RESP timing parameter [in DFI clocks], the maximum number of DFI clocks allowed for dfi_ctrlmsg_ack to assert after dfi_ctrlmsg_req goes high. FC=1 Reset Source: ctl_amod_g_rst_n
  [6:0] TDFI_CTRLMSG_RESP_F0 — Defines the DFI tCTRLMSG_RESP timing parameter [in DFI clocks], the maximum number of DFI clocks allowed for dfi_ctrlmsg_ack to assert after dfi_ctrlmsg_req goes high. FC=0 Reset Source: ctl_amod_g_rst_n
0x2000 DDR16SS_CTLPHY_WRAP_CTL_CFG_CTLCFG_DENALI_PI_0
  [11:8] PI_DRAM_CLASS — Defines the memory class for the PI. Reset Source: ctl_amod_g_rst_n
  [0] PI_START — Initiate command processing in the PI. Set to 1 to initiate. Reset Source: ctl_amod_g_rst_n
0x2004 DDR16SS_CTLPHY_WRAP_CTL_CFG_CTLCFG_DENALI_PI_1 ro reset 0xAE8D79E2
  [31:0] PI_VERSION_0 — Holds the PI version number. This is a unique number for each PHY IP delivery. This will help in identifying different version of the PHY IP. READ-ONLY Reset Source: ctl_amod_g_rst_n
0x2008 DDR16SS_CTLPHY_WRAP_CTL_CFG_CTLCFG_DENALI_PI_2 ro reset 0x714B570
  [31:0] PI_VERSION_1 — Holds the PI version number. This is a unique number for each PHY IP delivery. This will help in identifying different version of the PHY IP. READ-ONLY Reset Source: ctl_amod_g_rst_n
0x200C DDR16SS_CTLPHY_WRAP_CTL_CFG_CTLCFG_DENALI_PI_3 access per field reset 0x11387
  [24] PI_NORMAL_LVL_SEQ rw — Enable the PI to finish all the pending leveling before releasing the DFI bus. Reset Source: ctl_amod_g_rst_n
  [16] PI_RELEASE_DFI ro — This is a status whether PI has release DFI. READ-ONLY. Reset Source: ctl_amod_g_rst_n
  [15:0] PI_ID ro — Holds the PI ID number. This is a Cadence DDR PHY IP identifier. It is set to 0x1387. READ-ONLY Reset Source: ctl_amod_g_rst_n
0x2010 DDR16SS_CTLPHY_WRAP_CTL_CFG_CTLCFG_DENALI_PI_4
  [31:16] PI_TCMD_GAP — Specifies the minimum gap in DFI clocks between two commands. Used to guard the timing from the last command of MC and the first command of PI when MC hand over the control of DFI to PI. Reset Source: ctl_amod_g_rst_n
  [9:8] PI_NOTCARE_PHYUPD — Allow the PI to issue a master request to the controller if a phyupd_req from the PHY has been detected.bit[1] represents supports in normal state;bit[0] represents supports in initialization state. Set to 1 to issue the master request. Reset Source: ctl_amod_g_rst_n
  [0] PI_INIT_LVL_EN — Enables the initial leveling sequence after PI initialization procedure. Set to 1 to enable. Reset Source: ctl_amod_g_rst_n
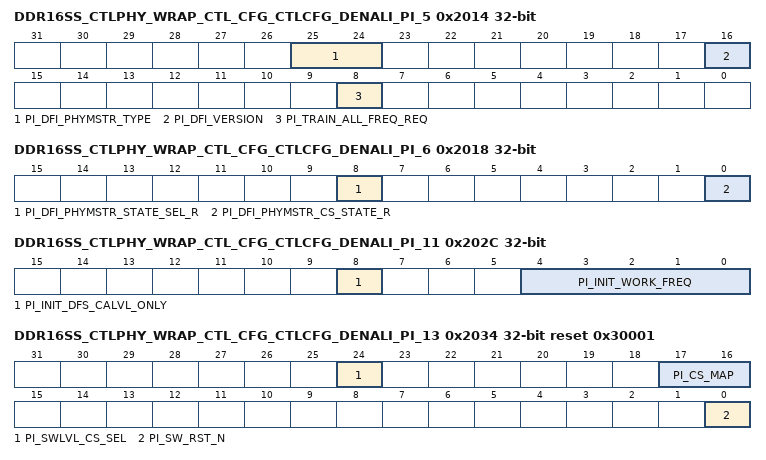
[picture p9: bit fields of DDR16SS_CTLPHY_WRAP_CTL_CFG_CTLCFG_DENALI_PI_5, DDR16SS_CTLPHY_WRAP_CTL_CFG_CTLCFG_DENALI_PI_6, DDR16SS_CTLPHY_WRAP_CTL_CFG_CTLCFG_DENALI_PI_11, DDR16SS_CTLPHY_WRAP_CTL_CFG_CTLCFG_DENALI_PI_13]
0x2014 DDR16SS_CTLPHY_WRAP_CTL_CFG_CTLCFG_DENALI_PI_5 access per field
  [25:24] PI_DFI_PHYMSTR_TYPE rw — DFI Master Request Type used for dfi 4.1 verision: This signal indicates the required state of DRAM when PHY becomes the master. Each memory rank uses one bit. 1'b0: IDLE. The MC should close all the pages. 1'b1: IDLE or Self Refresh. Reset Source: ctl_amod_g_rst_n
  [16] PI_DFI_VERSION rw — Define the DFI master version, set 1 for DFI4.1, set 0 for DFI4.0 Reset Source: ctl_amod_g_rst_n
  [8] PI_TRAIN_ALL_FREQ_REQ wo — Triggers training for all supported frequencies in PI_FREQ_MAP. Applies to LPDDR4 devices onlyh. Set to 1 to trigger. Only applicable after memory initialization has been completed. Can be used to train new frequencies that were not available at initialization time. WRITE-ONLY Reset Source: ctl_amod_g_rst_n
0x2018 DDR16SS_CTLPHY_WRAP_CTL_CFG_CTLCFG_DENALI_PI_6
  [8] PI_DFI_PHYMSTR_STATE_SEL_R — DFI PHY Master State Select: Indication from the PHY to the MC whether the requested memory state is IDLE or Self refresh. 'b0: indicates that the corresponding CS must be put into the IDLE state. 'b1: indicates that the corresponding CS must be put into the Self refresh state. Reset Source: ctl_amod_g_rst_n
  [0] PI_DFI_PHYMSTR_CS_STATE_R — This signal indicates the state of the DRAM when the PHY becomes the master. 'b0: The PHY specifies the required state, using the dfi_phymstr_state_sel signal. 'b1: is reserved. Reset Source: ctl_amod_g_rst_n
0x201C DDR16SS_CTLPHY_WRAP_CTL_CFG_CTLCFG_DENALI_PI_7 ro
  [31:0] PI_TDFI_PHYMSTR_MAX — Indicates the maximum number of DFI clock cycles registered while the dfi_phymstr_req signal is asserted and the dfi_phymstr_ack signal is asserted. READ-ONLY. Reset Source: ctl_amod_g_rst_n
0x2020 DDR16SS_CTLPHY_WRAP_CTL_CFG_CTLCFG_DENALI_PI_8 ro
  [19:0] PI_TDFI_PHYMSTR_RESP — Indicates the maximum number of DFI clock cycles registered between a dfi_phymstr_req signal assertion and a dfi_phymstr_ack signal assertion. READ-ONLY Reset Source: ctl_amod_g_rst_n
0x2024 DDR16SS_CTLPHY_WRAP_CTL_CFG_CTLCFG_DENALI_PI_9 ro
  [19:0] PI_TDFI_PHYUPD_RESP — Indicates the maximum number of DFI clock cycles registered between a dfi_phyupd_req signal assertion and a dfi_phyupd_ack signal assertion. READ-ONLY. Reset Source: ctl_amod_g_rst_n
0x2028 DDR16SS_CTLPHY_WRAP_CTL_CFG_CTLCFG_DENALI_PI_10 ro
  [31:0] PI_TDFI_PHYUPD_MAX — Indicates the maximum number of DFI clock cycles registered while the dfi_phyupd_req signal is asserted and the dfi_phy_ack signal is asserted. READ-ONLY. Reset Source: ctl_amod_g_rst_n
0x202C DDR16SS_CTLPHY_WRAP_CTL_CFG_CTLCFG_DENALI_PI_11
  [8] PI_INIT_DFS_CALVL_ONLY — Enables frequency training for CA leveling only. Other trainings are not performed. Reset Source: ctl_amod_g_rst_n
  [4:0] PI_INIT_WORK_FREQ — Indicates the initial work frequency after initialization and initial leveling sequence. Reset Source: ctl_amod_g_rst_n
0x2030 DDR16SS_CTLPHY_WRAP_CTL_CFG_CTLCFG_DENALI_PI_12
  [31:0] PI_FREQ_MAP — Frequency map for supported working frequencies. Each bit represents one supported frequency. Reset Source: ctl_amod_g_rst_n
0x2034 DDR16SS_CTLPHY_WRAP_CTL_CFG_CTLCFG_DENALI_PI_13 reset 0x30001
  [24] PI_SWLVL_CS_SEL — Defines which chip selects are active in swlvl, 0 for binary, 1 for one-hot. Reset Source: ctl_amod_g_rst_n
  [17:16] PI_CS_MAP — Defines which chip selects are active. Reset Source: ctl_amod_g_rst_n
  [0] PI_SW_RST_N — User request to reset the whole PI except the parameter modules. Set 0 to reset, set to 1 to release. Reset Source: ctl_amod_g_rst_n
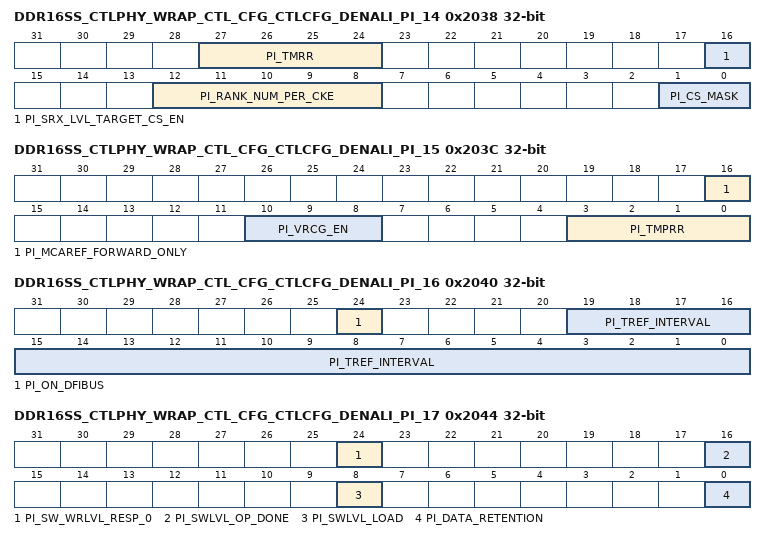
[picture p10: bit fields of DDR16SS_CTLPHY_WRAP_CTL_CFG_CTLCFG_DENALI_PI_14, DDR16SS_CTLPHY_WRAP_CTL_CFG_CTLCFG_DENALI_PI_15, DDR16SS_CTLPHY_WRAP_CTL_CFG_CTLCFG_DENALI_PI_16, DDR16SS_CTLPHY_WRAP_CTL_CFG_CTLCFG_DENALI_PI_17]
0x2038 DDR16SS_CTLPHY_WRAP_CTL_CFG_CTLCFG_DENALI_PI_14
  [27:24] PI_TMRR — DRAM tMRR value in memory clock cycles. Reset Source: ctl_amod_g_rst_n
  [16] PI_SRX_LVL_TARGET_CS_EN — Defines self refresh exit trigger target rank/ranks training or all ranks training. 1: The rank/ranks exit from self refresh will trigger the corresponding rank/ranks training. Note: If multiple ranks exit from self refresh, current design only support the multiple ranks srx command issues at the same time. 0: Any rank/ranks exit from self refresh will trigger all ranks training Reset Source: ctl_amod_g_rst_n
  [12:8] PI_RANK_NUM_PER_CKE — Defines the number of chip selects share one cke Reset Source: ctl_amod_g_rst_n
  [1:0] PI_CS_MASK — Defines which chip selects are active. Reset Source: ctl_amod_g_rst_n
0x203C DDR16SS_CTLPHY_WRAP_CTL_CFG_CTLCFG_DENALI_PI_15
  [16] PI_MCAREF_FORWARD_ONLY — Controls the generation of AREF from the PI module or forward the MC received value. Reset Source: ctl_amod_g_rst_n
  [10:8] PI_VRCG_EN — Whether enable VRCG mode in two cases: bit0 - when DFS. bit1-when setting DQ Vref. bit2-when setting CBT. Reset Source: ctl_amod_g_rst_n
  [3:0] PI_TMPRR — DRAM tMPRR value in memory clock cycles. Reset Source: ctl_amod_g_rst_n
0x2040 DDR16SS_CTLPHY_WRAP_CTL_CFG_CTLCFG_DENALI_PI_16 access per field
  [24] PI_ON_DFIBUS ro — Monitors the state of the PI controlling the DFI bus. 1 means PI is in control. READ-ONLY. Reset Source: ctl_amod_g_rst_n
  [19:0] PI_TREF_INTERVAL rw — Defines the cycles between refreshes to different chip selects. Reset Source: ctl_amod_g_rst_n
0x2044 DDR16SS_CTLPHY_WRAP_CTL_CFG_CTLCFG_DENALI_PI_17 access per field
  [24] PI_SW_WRLVL_RESP_0 ro — Write leveling response for data slice 0. READ-ONLY Reset Source: ctl_amod_g_rst_n
  [16] PI_SWLVL_OP_DONE ro — Reports the status of the software leveling operation. Value of 1 indicates operation complete. READ-ONLY Reset Source: ctl_amod_g_rst_n
  [8] PI_SWLVL_LOAD wo — User request to load delays and execute software leveling. Set to 1 to trigger. WRITE-ONLY Reset Source: ctl_amod_g_rst_n
  [0] PI_DATA_RETENTION ro — Monitors the readiness for the PHY to be put into data retention mode after pi_sref_entry req parameter has been written. 1 means ready for data retention. READ-ONLY. Reset Source: ctl_amod_g_rst_n
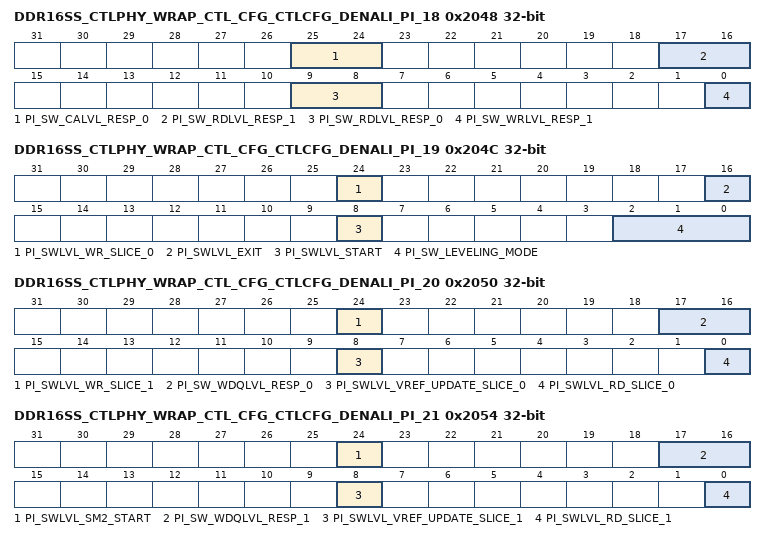
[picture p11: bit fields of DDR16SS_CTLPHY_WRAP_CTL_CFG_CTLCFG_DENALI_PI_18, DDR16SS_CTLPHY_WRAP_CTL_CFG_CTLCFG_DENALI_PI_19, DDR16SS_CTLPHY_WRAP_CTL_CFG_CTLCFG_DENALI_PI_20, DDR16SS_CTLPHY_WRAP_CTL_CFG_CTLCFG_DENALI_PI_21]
0x2048 DDR16SS_CTLPHY_WRAP_CTL_CFG_CTLCFG_DENALI_PI_18 ro
  [25:24] PI_SW_CALVL_RESP_0 — CA leveling response for address slice 0. READ-ONLY Reset Source: ctl_amod_g_rst_n
  [17:16] PI_SW_RDLVL_RESP_1 — Read leveling response for data slice 1. READ-ONLY Reset Source: ctl_amod_g_rst_n
  [9:8] PI_SW_RDLVL_RESP_0 — Read leveling response for data slice 0. READ-ONLY Reset Source: ctl_amod_g_rst_n
  [0] PI_SW_WRLVL_RESP_1 — Write leveling response for data slice 1. READ-ONLY Reset Source: ctl_amod_g_rst_n
0x204C DDR16SS_CTLPHY_WRAP_CTL_CFG_CTLCFG_DENALI_PI_19 access per field
  [24] PI_SWLVL_WR_SLICE_0 wo — SW leveling write command in WDQ training. WRITE-ONLY Reset Source: ctl_amod_g_rst_n
  [16] PI_SWLVL_EXIT wo — User request to exit software leveling. Set to 1 to exit. WRITE-ONLY Reset Source: ctl_amod_g_rst_n
  [8] PI_SWLVL_START wo — User request to initiate software leveling of type in the SW_LEVELING_MODE parameter. Set to 1 to trigger. WRITE-ONLY Reset Source: ctl_amod_g_rst_n
  [2:0] PI_SW_LEVELING_MODE rw — Defines the leveling operation for software leveling. Set to 'b111 for DDR4 VREF training, set to b001 for write leveling, set to b010 for read data eye training, or set to b011 for read gate training, set to b100 for ca training, set to b101 for wdq training. Reset Source: ctl_amod_g_rst_n
0x2050 DDR16SS_CTLPHY_WRAP_CTL_CFG_CTLCFG_DENALI_PI_20 access per field
  [24] PI_SWLVL_WR_SLICE_1 wo — SW leveling write command in WDQ training. WRITE-ONLY Reset Source: ctl_amod_g_rst_n
  [17:16] PI_SW_WDQLVL_RESP_0 ro — Leveling response for data slice 0. READ-ONLY Reset Source: ctl_amod_g_rst_n
  [8] PI_SWLVL_VREF_UPDATE_SLICE_0 wo — SW leveling vref update command in WDQ training. WRITE-ONLY Reset Source: ctl_amod_g_rst_n
  [0] PI_SWLVL_RD_SLICE_0 wo — SW leveling read command in WDQ training. WRITE-ONLY Reset Source: ctl_amod_g_rst_n
0x2054 DDR16SS_CTLPHY_WRAP_CTL_CFG_CTLCFG_DENALI_PI_21 access per field
  [24] PI_SWLVL_SM2_START wo — SW leveling start command for stage 2. WRITE-ONLY Reset Source: ctl_amod_g_rst_n
  [17:16] PI_SW_WDQLVL_RESP_1 ro — Leveling response for data slice 1. READ-ONLY Reset Source: ctl_amod_g_rst_n
  [8] PI_SWLVL_VREF_UPDATE_SLICE_1 wo — SW leveling vref update command in WDQ training. WRITE-ONLY Reset Source: ctl_amod_g_rst_n
  [0] PI_SWLVL_RD_SLICE_1 wo — SW leveling read command in WDQ training. WRITE-ONLY Reset Source: ctl_amod_g_rst_n
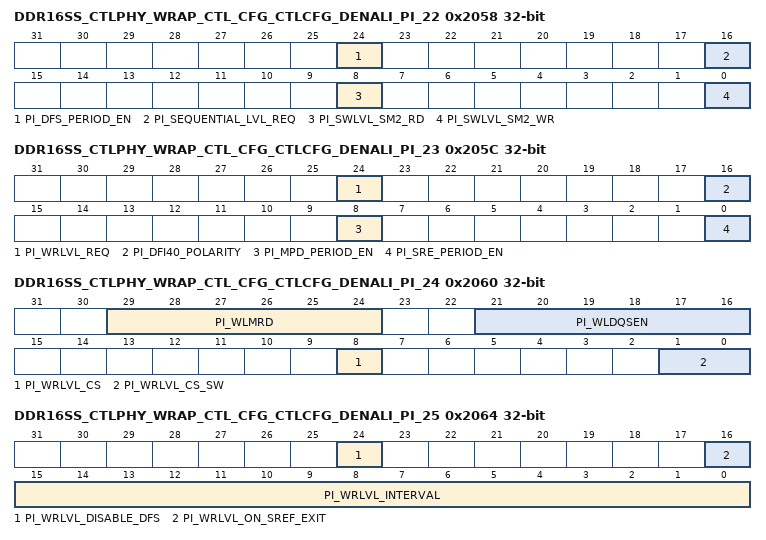
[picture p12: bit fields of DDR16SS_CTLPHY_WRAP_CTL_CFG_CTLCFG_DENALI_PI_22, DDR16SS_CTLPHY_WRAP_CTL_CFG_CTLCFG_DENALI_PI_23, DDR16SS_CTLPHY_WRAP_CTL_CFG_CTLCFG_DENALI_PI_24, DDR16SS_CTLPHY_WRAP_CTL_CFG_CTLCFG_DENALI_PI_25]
0x2058 DDR16SS_CTLPHY_WRAP_CTL_CFG_CTLCFG_DENALI_PI_22 access per field
  [24] PI_DFS_PERIOD_EN rw — Enable the DFS triggered periodic leveling. Reset Source: ctl_amod_g_rst_n
  [16] PI_SEQUENTIAL_LVL_REQ wo — User request to initiate all possible leveling sequences. Set to 1 to trigger. WRITE-ONLY Reset Source: ctl_amod_g_rst_n
  [8] PI_SWLVL_SM2_RD wo — SW leveling read command for stage 2. WRITE-ONLY Reset Source: ctl_amod_g_rst_n
  [0] PI_SWLVL_SM2_WR wo — SW leveling write command for stage 2. WRITE-ONLY Reset Source: ctl_amod_g_rst_n
0x205C DDR16SS_CTLPHY_WRAP_CTL_CFG_CTLCFG_DENALI_PI_23 access per field
  [24] PI_WRLVL_REQ wo — User request to initiate write leveling. Set to 1 to trigger. WRITE-ONLY Reset Source: ctl_amod_g_rst_n
  [16] PI_DFI40_POLARITY rw — Defines the polarity of the dfi_wrdata_cs_n/dfi_rddata_cs_n signals. Reset Source: ctl_amod_g_rst_n
  [8] PI_MPD_PERIOD_EN rw — Enable the max power saving mode exit triggered periodic leveling. Reset Source: ctl_amod_g_rst_n
  [0] PI_SRE_PERIOD_EN rw — Enable the self refresh exit triggered periodic leveling. Reset Source: ctl_amod_g_rst_n
0x2060 DDR16SS_CTLPHY_WRAP_CTL_CFG_CTLCFG_DENALI_PI_24
  [29:24] PI_WLMRD — Delay from issuing MRS to first write leveling strobe. Reset Source: ctl_amod_g_rst_n
  [21:16] PI_WLDQSEN — Delay from issuing MRS to first DQS strobe for write leveling. Reset Source: ctl_amod_g_rst_n
  [8] PI_WRLVL_CS — Specifies the target chip select for the write leveling operation initiated through the WRLVL_REQ parameter. Reset Source: ctl_amod_g_rst_n
  [1:0] PI_WRLVL_CS_SW — Specifies the target chip select for the write leveling operation initiated through the WRLVL_REQ parameter. Reset Source: ctl_amod_g_rst_n
0x2064 DDR16SS_CTLPHY_WRAP_CTL_CFG_CTLCFG_DENALI_PI_25
  [24] PI_WRLVL_DISABLE_DFS — Disable automatic write leveling on freq change. Set to 1 to disable wrlvl on dfs,set 0 enable wrlvl on dfs. Reset Source: ctl_amod_g_rst_n
  [16] PI_WRLVL_ON_SREF_EXIT — Enables automatic write leveling on a self-refresh exit. Set to 1 to enable. Reset Source: ctl_amod_g_rst_n
  [15:0] PI_WRLVL_INTERVAL — Number of long count sequences counted between automatic write leveling commands. Reset Source: ctl_amod_g_rst_n
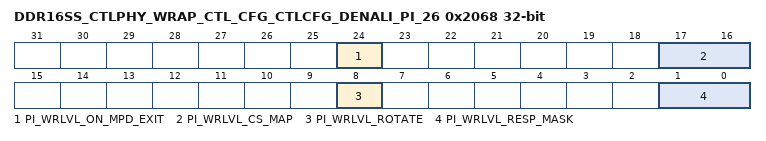
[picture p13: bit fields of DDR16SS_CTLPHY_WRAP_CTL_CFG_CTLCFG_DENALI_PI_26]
0x2068 DDR16SS_CTLPHY_WRAP_CTL_CFG_CTLCFG_DENALI_PI_26
  [24] PI_WRLVL_ON_MPD_EXIT — Enables automatic write leveling on a maximum power down mode exit. Set to 1 to enable. Reset Source: ctl_amod_g_rst_n
  [17:16] PI_WRLVL_CS_MAP — Defines the chip select map for write leveling operations. Bit [0] controls cs0, bit [1] controls cs1, etc. Set each bit to 1 to enable chip for write leveling. Reset Source: ctl_amod_g_rst_n
  [8] PI_WRLVL_ROTATE — Enables rotational CS for counter triggered automatic write leveling. Set to 1, only one rank's write levling will process, the rank number is rotational for each time that write leveling been triggered by counter expiring. Set to 0 or not a short pattern leveling [indicated by dfi_lvl_periodic], the counter expired write leveling will process all the ranks. Reset Source: ctl_amod_g_rst_n
  [1:0] PI_WRLVL_RESP_MASK — Mask for the dfi_wrlvl_resp signal during write leveling. Reset Source: ctl_amod_g_rst_n
